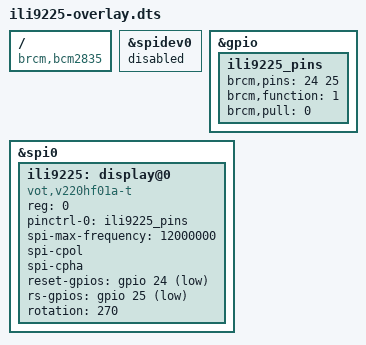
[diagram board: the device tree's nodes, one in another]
/dts-v1/;
/plugin/;

/ {
	compatible = "brcm,bcm2835";

	/* Disable conflicting spidev0 (CE0) */
	fragment@0 {
		target = <&spidev0>;
		__overlay__ {
			status = "disabled";
		};
	};

	/* Define GPIO pins for display control */
	fragment@1 {
		target = <&gpio>;
			__overlay__ {
				ili9225_pins: ili9225_pins {
					brcm,pins = <24 25>;        /* GPIO24=reset, GPIO25=rs */
					brcm,function = <1>;        /* 1 = output */
					brcm,pull = <0>;            /* no pull */
			};
		};
	};

	/* Configure SPI0 and add ili9225 display device */
	fragment@2 {
		target = <&spi0>;
		__overlay__ {
			status = "okay";
			#address-cells = <1>;
			#size-cells = <0>;

			ili9225: display@0 {
				compatible = "vot,v220hf01a-t", "ilitek,ili9225";
				reg = <0>;                          /* CE0 chip select */
				pinctrl-names = "default";
				pinctrl-0 = <&ili9225_pins>;

				spi-max-frequency = <12000000>;
				spi-cpol;
				spi-cpha;

				reset-gpios = <&gpio 24 1>;
				rs-gpios = <&gpio 25 1>;  /* Data/Command line */
				rotation = <270>;
				status = "okay";
			};
		};
	};

/* Runtime parameter overrides */
	__overrides__ {
		speed = <&ili9225>, "spi-max-frequency:0";
		rotation = <&ili9225>, "rotation:0";
	};
};
